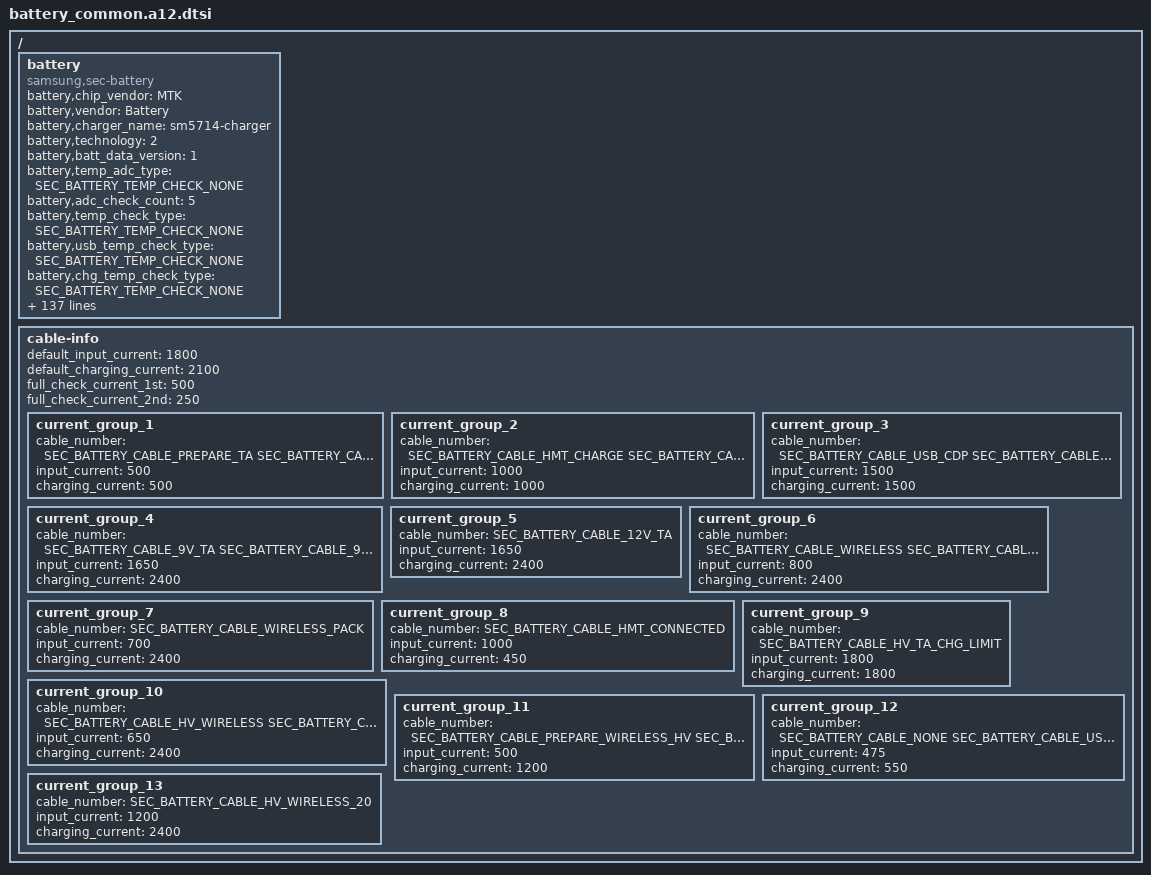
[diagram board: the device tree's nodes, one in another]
#include <dt-bindings/battery/sec_battery_param_define.h>

/ {
	fragment@smd {
		target-path = "/";
		__overlay__ {
			battery {
				pinctrl-names = "default";

				battery,chip_vendor = "MTK";
				status = "okay";
				compatible = "samsung,sec-battery";
				battery,vendor = "Battery";
				battery,charger_name = "sm5714-charger";
				battery,technology = <2>; /* POWER_SUPPLY_TECHNOLOGY_LION */

				battery,batt_data_version = <1>;

				battery,temp_adc_type = <SEC_BATTERY_TEMP_CHECK_NONE>; /* SEC_BATTERY_ADC_TYPE_AP */
				battery,adc_check_count = <5>;
				battery,temp_check_type = <SEC_BATTERY_TEMP_CHECK_NONE>;
				battery,usb_temp_check_type = <SEC_BATTERY_TEMP_CHECK_NONE>;
				battery,chg_temp_check_type = <SEC_BATTERY_TEMP_CHECK_NONE>;
				battery,wpc_temp_check_type = <SEC_BATTERY_TEMP_CHECK_NONE>;

				battery,thermal_source = <SEC_BATTERY_THERMAL_SOURCE_NONE>; /* SEC_BATTERY_THERMAL_SOURCE_NONE */
				battery,usb_thermal_source = <SEC_BATTERY_THERMAL_SOURCE_NONE>; /* SEC_BATTERY_THERMAL_SOURCE_NONE */
				battery,chg_thermal_source = <SEC_BATTERY_THERMAL_SOURCE_NONE>; /* SEC_BATTERY_THERMAL_SOURCE_NONE */
				battery,wpc_thermal_source = <SEC_BATTERY_THERMAL_SOURCE_NONE>; /* SEC_BATTERY_THERMAL_SOURCE_NONE */

				battery,polling_time = <10 30 30 30 3600>;

				battery,cable_check_type = <4>; /* SEC_BATTERY_CABLE_CHECK_PSY */
				battery,cable_source_type = <SEC_BATTERY_CABLE_SOURCE_EXTERNAL>;
				battery,polling_type = <SEC_BATTERY_MONITOR_ALARM>; /* SEC_BATTERY_MONITOR_ALARM */
				battery,monitor_initial_count = <0>;

				battery,battery_check_type = <0>; /* SEC_BATTERY_CHECK_NONE */

				battery,ovp_uvlo_check_type = <SEC_BATTERY_OVP_UVLO_CHGPOLLING>; /* SEC_BATTERY_OVP_UVLO_CHGPOLLING */

				battery,temp_check_count = <1>;
				battery,temp_highlimit_threshold_event = <800>;
				battery,temp_highlimit_recovery_event = <780>;
				battery,temp_high_threshold_event = <500>;
				battery,temp_high_recovery_event = <480>;
				battery,temp_low_threshold_event = <0>;
				battery,temp_low_recovery_event = <20>;
				battery,temp_highlimit_threshold_normal = <800>;
				battery,temp_highlimit_recovery_normal = <780>;
				battery,temp_high_threshold_normal = <500>;
				battery,temp_high_recovery_normal = <480>;
				battery,temp_low_threshold_normal = <0>;
				battery,temp_low_recovery_normal = <20>;
				battery,temp_highlimit_threshold_lpm = <800>;
				battery,temp_highlimit_recovery_lpm = <780>;
				battery,temp_high_threshold_lpm = <500>;
				battery,temp_high_recovery_lpm = <480>;
				battery,temp_low_threshold_lpm = <0>;
				battery,temp_low_recovery_lpm = <20>;
				battery,wpc_high_threshold_normal = <450>;
				battery,wpc_high_recovery_normal = <430>;
				battery,wpc_low_threshold_normal = <0>;
				battery,wpc_low_recovery_normal = <20>;
				battery,full_check_type = <SEC_BATTERY_FULLCHARGED_CHGPSY>;
				battery,full_check_type_2nd = <SEC_BATTERY_FULLCHARGED_CHGPSY>;
				battery,full_check_count = <1>;
				battery,chg_gpio_full_check = <0>;
				battery,chg_polarity_full_check = <1>;

				battery,chg_high_temp = <460>;
				battery,chg_high_temp_recovery = <440>;
				battery,chg_input_limit_current = <1000>;
				battery,chg_charging_limit_current = <1400>;

				battery,wpc_temp_control_source = <TEMP_CONTROL_SOURCE_BAT_THM>;
				battery,wpc_high_temp = <380>;
				battery,wpc_high_temp_recovery = <360>;
				battery,wpc_input_limit_current = <600>;
				battery,wpc_charging_limit_current = <1000>;
				battery,wpc_temp_lcd_on_control_source = <TEMP_CONTROL_SOURCE_BAT_THM>;
				battery,wpc_lcd_on_high_temp = <380>;
				battery,wpc_lcd_on_high_temp_rec = <360>;
				battery,wpc_lcd_on_input_limit_current = <450>;

				battery,wpc_store_high_temp = <360>;
				battery,wpc_store_high_temp_recovery = <340>;
				battery,wpc_store_charging_limit_current = <400>;
				battery,wpc_store_lcd_on_high_temp = <360>;
				battery,wpc_store_lcd_on_high_temp_rec = <300>;
				battery,wpc_store_lcd_on_charging_limit_current = <400>;

				battery,sleep_mode_limit_current = <500>;
				battery,wc_full_input_limit_current = <100>;

				battery,mix_high_temp = <420>;
				battery,mix_high_chg_temp = <500>;
				battery,mix_high_temp_recovery = <390>;

				battery,full_condition_type = <(SEC_BATTERY_FULL_CONDITION_NOTIMEFULL | SEC_BATTERY_FULL_CONDITION_VCELL)>;
				battery,full_condition_soc = <93>;
				battery,full_condition_vcell = <4250>;

				battery,recharge_check_count = <1>;
				battery,recharge_condition_type = <SEC_BATTERY_RECHARGE_CONDITION_VCELL>;
				battery,recharge_condition_soc = <98>;
				battery,recharge_condition_vcell = <4280>;

				battery,charging_total_time = <14400>;
				battery,hv_charging_total_time = <10800>;
				battery,normal_charging_total_time = <18000>;
				battery,usb_charging_total_time = <36000>;
				battery,recharging_total_time = <5400>;
				battery,charging_reset_time = <0>;

				battery,chg_float_voltage = <4350>;

				battery,pre_afc_work_delay = <2000>;
				battery,pre_wc_afc_work_delay = <4000>;
				battery,pre_afc_input_current = <500>;
				battery,pre_wc_afc_input_current = <500>;
				battery,prepare_ta_delay = <0>; /* msec */

				battery,swelling_high_temp_block = <410>;
				battery,swelling_high_temp_recov = <390>;
				battery,swelling_low_temp_block_1st = <150>;
				battery,swelling_low_temp_recov_1st = <170>;
				battery,swelling_low_temp_block_2nd = <50>;
				battery,swelling_low_temp_recov_2nd = <70>;

				battery,swelling_drop_float_voltage = <4150>;
				battery,swelling_high_rechg_voltage = <4000>;
				battery,swelling_low_rechg_voltage = <4000>;

				battery,siop_input_limit_current = <1200>;
				battery,siop_charging_limit_current = <1000>;
				battery,siop_hv_input_limit_current = <700>;
				battery,siop_hv_input_limit_current_2nd = <550>;
				battery,siop_hv_charging_limit_current = <1000>;

				battery,rp_current_rp1 = <500>;
				battery,rp_current_rp2 = <1500>;
				battery,rp_current_rp3 = <3000>;
				battery,rp_current_rdu_rp3 = <2100>;
				battery,rp_current_abnormal_rp3 = <1800>;

				battery,pd_charging_charge_power = <15000>;
				battery,max_charging_current = <2400>;

				battery,wireless_cc_cv = <85>;
				battery,wireless_otg_input_current = <900>;

				/* cycle, chg_float_voltage, recharge_condition_vcell, full_condition_vcell, full_condition_soc, step charging condition */
				battery,age_data = <0 4380 4310 4280 93
					300 4360 4290 4260 92
					400 4340 4270 4240 91
					700 4320 4250 4220 90
					1000 4270 4200 4170 89>;

				battery,health_condition = <
					/* CYCLE ASOC */
					900 0  /* GOOD */
					1200 0 /* NORMAL */
					1500 0 /* AGED */
					>;

				battery,standard_curr = <2400>;
				battery,expired_time = <13800>; /* 160 + 70 minutes */
				battery,recharging_expired_time = <5400>;
				battery,battery_full_capacity = <5000>;
				battery,cisd_max_voltage_thr = <5000>; /* batttery ovp dettection voltage */

				battery,max_input_voltage = <9000>; /* mV */
				battery,max_input_current = <3000>;  /* mA */

				battery,cisd_alg_index = <8>;
				battery,ignore_cisd_index = <0 960>; /* Do not use AFC_FAIL to DROP_VALUE */
				battery,ignore_cisd_index_d = <0 120>; /* Do not use AFC_FAIL_PER_DAY to DROP_VALUE_PER_DAY */

				battery,ttf_capacity = <3300>;
				battery,cv_data = <
							2488	809	1809
							2409	812	1796
							2327	817	1769
							2272	820	1743
							2182	826	1721
							2104	830	1690
							2038	834	1670
							1950	839	1640
							1904	841	1622
							1838	845	1594
							1797	847	1576
							1749	850	1560
							1683	853	1531
							1660	855	1525
							1653	856	1515
							1615	858	1512
							1580	860	1509
							1553	861	1502
							1544	862	1483
							1520	863	1463
							1477	866	1458
							1431	868	1451
							1396	871	1424
							1347	874	1409
							1299	876	1383
							1267	878	1361
							1231	882	1332
							1202	884	1315
							1148	886	1288
							1109	889	1263
							1067	891	1243
							1031	894	1213
							1013	895	1185
							975	897	1156
							961	899	1140
							921	901	1111
							892	903	1084
							887	903	1064
							863	905	1038
							833	907	1019
							808	909	1004
							787	910	976
							764	912	946
							744	914	918
							730	915	904
							715	916	895
							693	917	864
							681	918	846
							666	920	828
							651	921	800
							640	922	783
							628	925	752
							622	926	735
							618	927	712
							600	930	697
							596	931	679
							584	933	664
							576	936	646
							577	937	627
							562	938	614
							511	948	601
							505	949	572
							493	951	553
							492	952	535
							484	953	506
							480	955	487
							474	956	464
							462	957	435
							456	958	417
							452	959	398
							446	961	380
							437	962	364
							429	964	355
							423	965	336
							422	966	329
							414	967	303
							411	968	282
							405	969	255
							397	970	242
							391	971	229
							387	972	211
							384	973	199
							372	975	191
							364	977	171
							356	978	140
							350	981	126
							340	985	107
							335	988	84
							327	991	54
							320	995	26
							313	998	13
							0	1000	0
							>;

			/*	io-channels = ${adc[@]}(arrayprop);
				io-channel-names = ${adc_name[@]}(stringlist); */
			};

			/* sec_battery_cable
			 *   0	UNKNOWN,
			 *   1	NONE,
			 *   2	PREPARE_TA,
			 *   3	TA,
			 *   4	USB,
			 *   5	USB_CDP,
			 *   6	9V_TA,
			 *   7	9V_ERR,
			 *   8	9V_UNKNOWN,
			 *   9	12V_TA,
			 *  10	WIRELESS,
			 *  11	HV_WIRELESS,
			 *  12	PMA_WIRELESS,
			 *  13	WIRELESS_PACK,
			 *  14	CABLE_WIRELESS_HV_PACK,
			 *  15	WIRELESS_STAND,
			 *  16	WIRELESS_HV_STAND,
			 *  17	QC20,
			 *  18	QC30,
			 *  19	PDIC,
			 *  20	UARTOFF,
			 *  21	OTG,
			 *  22	LAN_HUB,
			 *  23	POWER_SHARING,
			 *  24	HMT_CONNECTED,
			 *  25	HMT_CHARGE,
			 *  26	HV_TA_CHG_LIMIT,
			 *  27	WIRELESS_VEHICLE,
			 *  28	WIRELESS_HV_VEHICLE,
			 *  29	PREPARE_WIRELESS_HV,
			 *  30  TIMEOUT,
			 *  31  SMART_OTG,
			 *  32  SMART_NOTG,
			 *  33  WIRELESS_TX,
			 *  34	HV_WIRELESS_20,
			 *  35	HV_WIRELESS_20_LIMIT,
			 *  36	WIRELESS_FAKE,
			 *  37  PREPARE_WIRELESS_20,
			 *  38	CABLE_PDIC_APDO,
			 *  39	CABLE_MAX,
			 */
			cable-info {
				default_input_current = <1800>;
				default_charging_current = <2100>;
				full_check_current_1st = <500>;
				full_check_current_2nd = <250>;

				current_group_1 {
					cable_number = <
						SEC_BATTERY_CABLE_PREPARE_TA
						SEC_BATTERY_CABLE_PDIC
						SEC_BATTERY_CABLE_OTG
						SEC_BATTERY_CABLE_LAN_HUB
						SEC_BATTERY_CABLE_POWER_SHARING>;
					input_current = <500>;
					charging_current = <500>;
				};
				current_group_2 {
					cable_number = <
						SEC_BATTERY_CABLE_HMT_CHARGE
						SEC_BATTERY_CABLE_SMART_OTG>;
					input_current = <1000>;
					charging_current = <1000>;
				};
				current_group_3 {
					cable_number = <
						SEC_BATTERY_CABLE_USB_CDP
						SEC_BATTERY_CABLE_SMART_NOTG>;
					input_current = <1500>;
					charging_current = <1500>;
				};
				current_group_4 {
					cable_number = <SEC_BATTERY_CABLE_9V_TA SEC_BATTERY_CABLE_9V_ERR
						SEC_BATTERY_CABLE_9V_UNKNOWN SEC_BATTERY_CABLE_QC20 SEC_BATTERY_CABLE_QC30>;
					input_current = <1650>;
					charging_current = <2400>;
				};
				current_group_5 {
					cable_number = <SEC_BATTERY_CABLE_12V_TA>;
					input_current = <1650>;
					charging_current = <2400>;
				};
				current_group_6 {
					cable_number = <
						SEC_BATTERY_CABLE_WIRELESS
						SEC_BATTERY_CABLE_PMA_WIRELESS
						SEC_BATTERY_CABLE_WIRELESS_STAND
						SEC_BATTERY_CABLE_WIRELESS_VEHICLE
						SEC_BATTERY_CABLE_WIRELESS_TX
						SEC_BATTERY_CABLE_WIRELESS_FAKE>;
					input_current = <800>;
					charging_current = <2400>;
				};
				current_group_7 {
					cable_number = <SEC_BATTERY_CABLE_WIRELESS_PACK>;
					input_current = <700>;
					charging_current = <2400>;
				};
				current_group_8 {
					cable_number = <SEC_BATTERY_CABLE_HMT_CONNECTED>;
					input_current = <1000>;
					charging_current = <450>;
				};
				current_group_9 {
					cable_number = <SEC_BATTERY_CABLE_HV_TA_CHG_LIMIT>;
					input_current = <1800>;
					charging_current = <1800>;
				};
				current_group_10 {
					cable_number = <
						SEC_BATTERY_CABLE_HV_WIRELESS
						SEC_BATTERY_CABLE_WIRELESS_HV_PACK
						SEC_BATTERY_CABLE_WIRELESS_HV_STAND
						SEC_BATTERY_CABLE_WIRELESS_HV_VEHICLE
						SEC_BATTERY_CABLE_HV_WIRELESS_20_LIMIT>;
					input_current = <650>;
					charging_current = <2400>;
				};
				current_group_11 {
					cable_number = <
						SEC_BATTERY_CABLE_PREPARE_WIRELESS_HV
						SEC_BATTERY_CABLE_PREPARE_WIRELESS_20>;
					input_current = <500>;
					charging_current = <1200>;
				};
				current_group_12 {
					cable_number = <
						SEC_BATTERY_CABLE_NONE
						SEC_BATTERY_CABLE_USB
						SEC_BATTERY_CABLE_TIMEOUT>;
					input_current = <475>;
					charging_current = <550>;
				};
				current_group_13 {
					cable_number = <SEC_BATTERY_CABLE_HV_WIRELESS_20>;
					input_current = <1200>;
					charging_current = <2400>;
				};
			};
		};
	};
};
